# STM32G431C6T6 register map
File version: 1.0
Registers are 32-bit, access not given, reset 0x0 unless marked. A register's access mark holds for its fields unless they carry their own. Offsets are from the block's base; [hi:lo] are bit positions; {n}, {i} and the like mark numbered series; 'fields as' and 'values as' point back to an identical list.

## OPAMP
Base 0x40010300
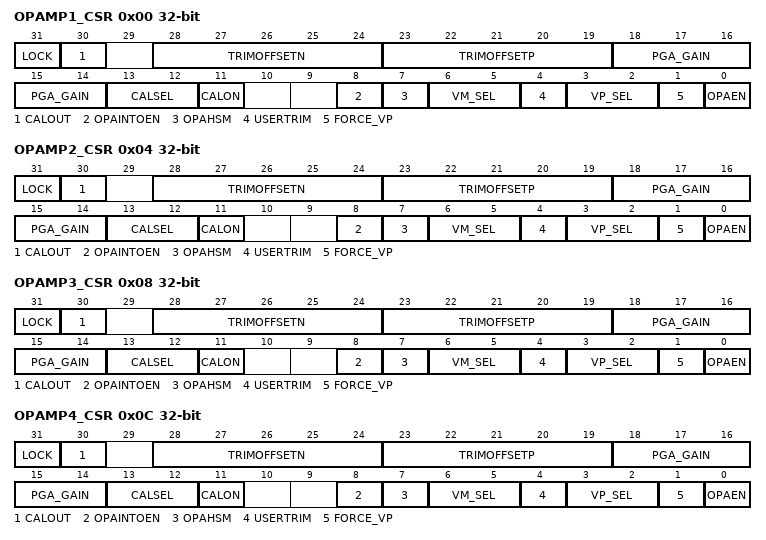
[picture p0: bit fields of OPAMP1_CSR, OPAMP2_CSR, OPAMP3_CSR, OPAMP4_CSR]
0x00 OPAMP1_CSR
  [31] LOCK, [30] CALOUT, [28:24] TRIMOFFSETN, [23:19] TRIMOFFSETP, [18:14] PGA_GAIN, [13:12] CALSEL, [11] CALON, [8] OPAINTOEN, [7] OPAHSM, [6:5] VM_SEL, [4] USERTRIM, [3:2] VP_SEL, [1] FORCE_VP, [0] OPAEN
0x04 OPAMP2_CSR
  fields as OPAMP1_CSR
0x08 OPAMP3_CSR
  fields as OPAMP1_CSR
0x0C OPAMP4_CSR
  fields as OPAMP1_CSR
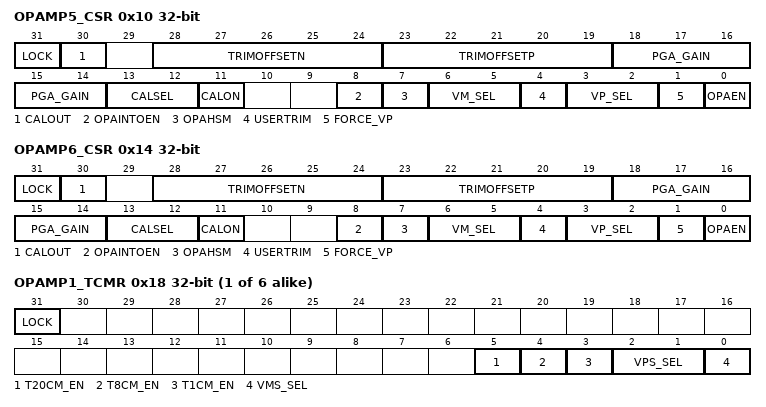
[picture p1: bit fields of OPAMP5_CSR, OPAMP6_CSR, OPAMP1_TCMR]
0x10 OPAMP5_CSR
  fields as OPAMP1_CSR
0x14 OPAMP6_CSR
  fields as OPAMP1_CSR
{0x14+4i} OPAMP{i}_TCMR (i=1..6)
  [31] LOCK, [5] T20CM_EN, [4] T8CM_EN, [3] T1CM_EN, [2:1] VPS_SEL, [0] VMS_SEL

## EXTI
Base 0x40010400
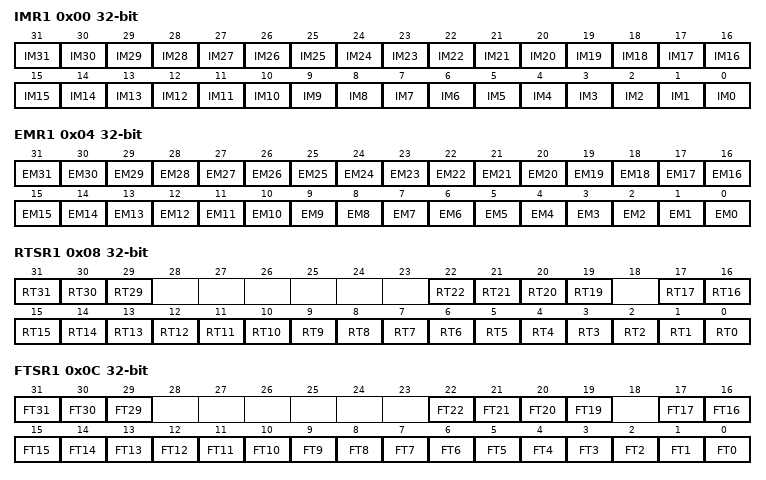
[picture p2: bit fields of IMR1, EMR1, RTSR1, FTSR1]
0x00 IMR1
  [n] IM{n} (n=0..31)
0x04 EMR1
  [n] EM{n} (n=0..31)
0x08 RTSR1
  [31] RT31, [30] RT30, [29] RT29, [n] RT{n} (n=19..22), [n] RT{n} (n=0..17)
0x0C FTSR1
  [31] FT31, [30] FT30, [29] FT29, [n] FT{n} (n=19..22), [n] FT{n} (n=0..17)
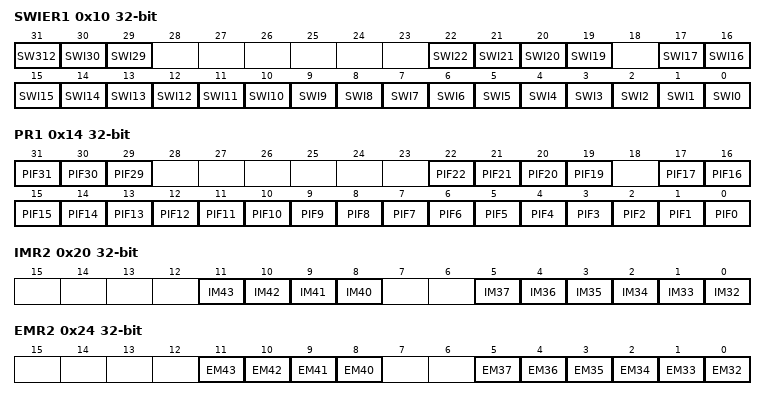
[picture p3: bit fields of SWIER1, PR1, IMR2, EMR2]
0x10 SWIER1
  [31] SW312, [30] SWI30, [29] SWI29, [n] SWI{n} (n=19..22), [n] SWI{n} (n=0..17)
0x14 PR1
  [31] PIF31, [30] PIF30, [29] PIF29, [n] PIF{n} (n=19..22), [n] PIF{n} (n=0..17)
0x20 IMR2
  [n-32] IM{n} (n=40..43), [n-32] IM{n} (n=32..37)
0x24 EMR2
  [n-32] EM{n} (n=40..43), [n-32] EM{n} (n=32..37)
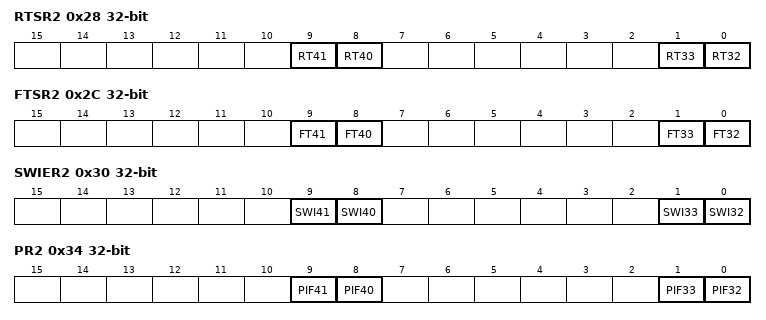
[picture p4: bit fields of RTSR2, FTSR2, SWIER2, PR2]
0x28 RTSR2
  [9] RT41, [8] RT40, [1] RT33, [0] RT32
0x2C FTSR2
  [9] FT41, [8] FT40, [1] FT33, [0] FT32
0x30 SWIER2
  [9] SWI41, [8] SWI40, [1] SWI33, [0] SWI32
0x34 PR2
  [9] PIF41, [8] PIF40, [1] PIF33, [0] PIF32

## TIM15
Base 0x40014000
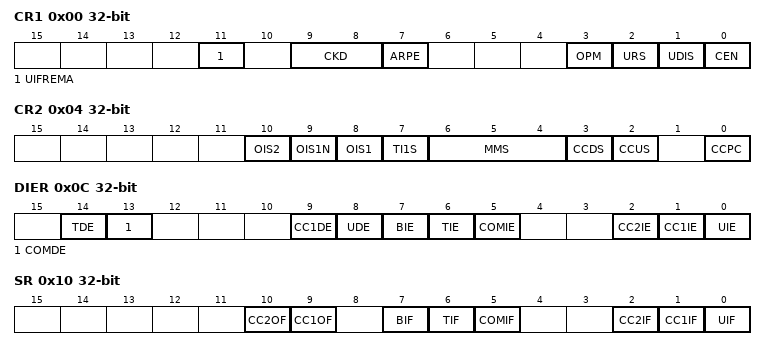
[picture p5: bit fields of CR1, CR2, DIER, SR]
0x00 CR1
  [11] UIFREMA, [9:8] CKD, [7] ARPE, [3] OPM, [2] URS, [1] UDIS, [0] CEN
0x04 CR2
  [10] OIS2, [9] OIS1N, [8] OIS1, [7] TI1S, [6:4] MMS, [3] CCDS, [2] CCUS, [0] CCPC
0x08 SMCR
  [7] MSM, [21:4] TS, [16:0] SMS
0x0C DIER
  [14] TDE, [13] COMDE, [9] CC1DE, [8] UDE, [7] BIE, [6] TIE, [5] COMIE, [2] CC2IE, [1] CC1IE, [0] UIE
0x10 SR
  [10] CC2OF, [9] CC1OF, [7] BIF, [6] TIF, [5] COMIF, [2] CC2IF, [1] CC1IF, [0] UIF
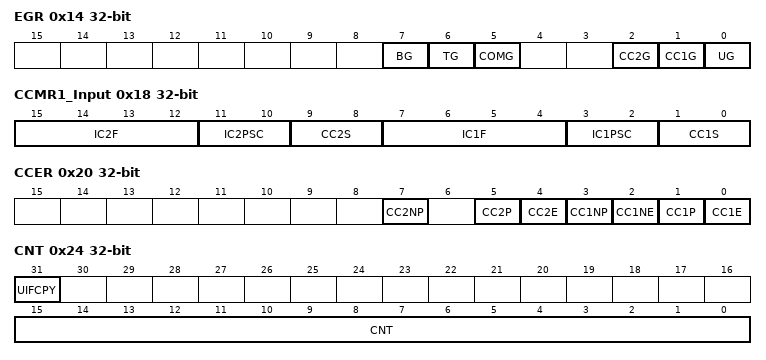
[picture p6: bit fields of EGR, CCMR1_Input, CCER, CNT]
0x14 EGR
  [7] BG, [6] TG, [5] COMG, [2] CC2G, [1] CC1G, [0] UG
0x18 CCMR1_Input
  [15:12] IC2F, [11:10] IC2PSC, [9:8] CC2S, [7:4] IC1F, [3:2] IC1PSC, [1:0] CC1S
0x18 CCMR1_Output
  [15] OC2CE, [24:12] OC2M, [11] OC2PE, [10] OC2FE, [9:8] CC2S, [7] OC1CE, [16:4] OC1M, [3] OC1PE, [2] OC1FE, [1:0] CC1S
0x20 CCER
  [7] CC2NP, [5] CC2P, [4] CC2E, [3] CC1NP, [2] CC1NE, [1] CC1P, [0] CC1E
0x24 CNT
  [31] UIFCPY, [15:0] CNT
0x28 PSC
  [15:0] PSC
0x2C ARR
  [19:0] ARR
0x30 RCR
  [7:0] REP
0x34 CCR1
  [19:0] CCR1
0x38 CCR2
  [19:0] CCR2
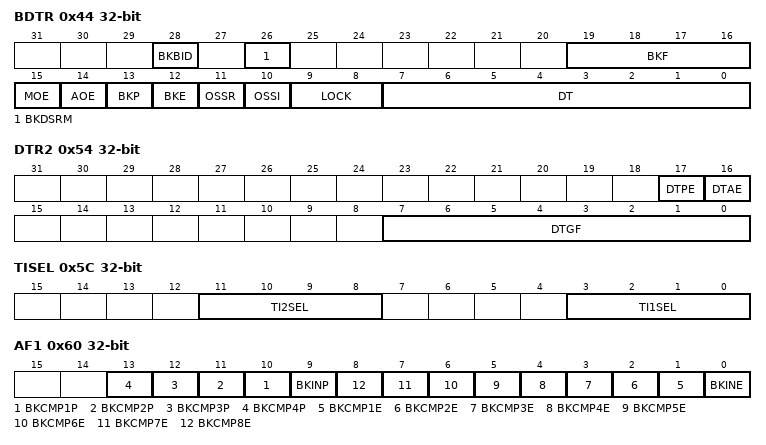
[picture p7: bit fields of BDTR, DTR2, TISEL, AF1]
0x44 BDTR
  [28] BKBID, [26] BKDSRM, [19:16] BKF, [15] MOE, [14] AOE, [13] BKP, [12] BKE, [11] OSSR, [10] OSSI, [9:8] LOCK, [7:0] DT
0x54 DTR2
  [17] DTPE, [16] DTAE, [7:0] DTGF
0x5C TISEL
  [11:8] TI2SEL, [3:0] TI1SEL
0x60 AF1
  [n+9] BKCMP{n}P (n=1..4), [9] BKINP, [n] BKCMP{n}E (n=1..8), [0] BKINE
0x64 AF2
  [18:16] OCRSEL
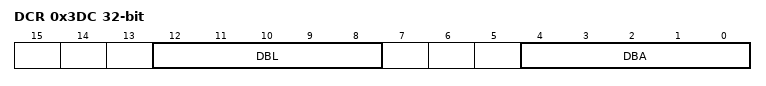
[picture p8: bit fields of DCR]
0x3DC DCR
  [12:8] DBL, [4:0] DBA
0x3E0 DMAR
  [31:0] DMAB

## TIM16
Base 0x40014400
Same registers: TIM17 0x40014800
Registers as TIM15, without SMCR, CCR2; these are added or differ:
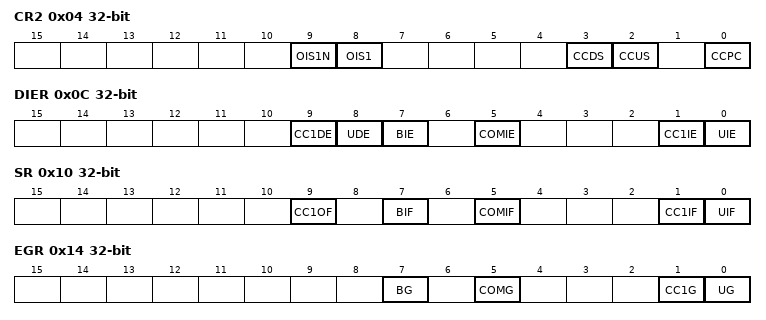
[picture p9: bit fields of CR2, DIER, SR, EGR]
0x04 CR2
  [9] OIS1N, [8] OIS1, [3] CCDS, [2] CCUS, [0] CCPC
0x0C DIER
  [9] CC1DE, [8] UDE, [7] BIE, [5] COMIE, [1] CC1IE, [0] UIE
0x10 SR
  [9] CC1OF, [7] BIF, [5] COMIF, [1] CC1IF, [0] UIF
0x14 EGR
  [7] BG, [5] COMG, [1] CC1G, [0] UG
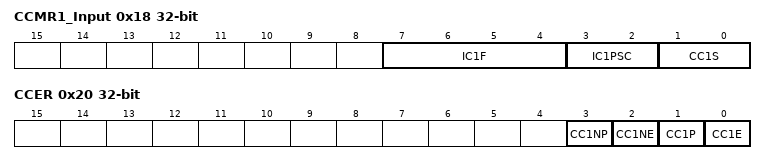
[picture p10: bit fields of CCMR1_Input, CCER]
0x18 CCMR1_Input
  [7:4] IC1F, [3:2] IC1PSC, [1:0] CC1S
0x18 CCMR1_Output
  [7] OC1CE, [16:4] OC1M, [3] OC1PE, [2] OC1FE, [1:0] CC1S
0x20 CCER
  [3] CC1NP, [2] CC1NE, [1] CC1P, [0] CC1E
0x5C TISEL
  [3:0] TI1SEL
0x68 OR1
  [0] HSE32EN

## SAI1
Base 0x40015400
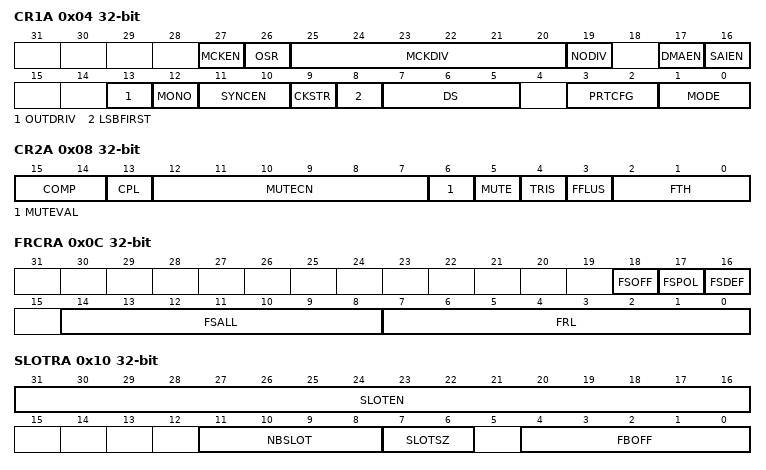
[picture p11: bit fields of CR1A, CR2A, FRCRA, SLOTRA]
0x04 CR1A
  [27] MCKEN, [26] OSR, [25:20] MCKDIV, [19] NODIV, [17] DMAEN, [16] SAIEN, [13] OUTDRIV, [12] MONO, [11:10] SYNCEN, [9] CKSTR, [8] LSBFIRST, [7:5] DS, [3:2] PRTCFG, [1:0] MODE
0x08 CR2A
  [15:14] COMP, [13] CPL, [12:7] MUTECN, [6] MUTEVAL, [5] MUTE, [4] TRIS, [3] FFLUS, [2:0] FTH
0x0C FRCRA
  [18] FSOFF, [17] FSPOL, [16] FSDEF, [14:8] FSALL, [7:0] FRL
0x10 SLOTRA
  [31:16] SLOTEN, [11:8] NBSLOT, [7:6] SLOTSZ, [4:0] FBOFF
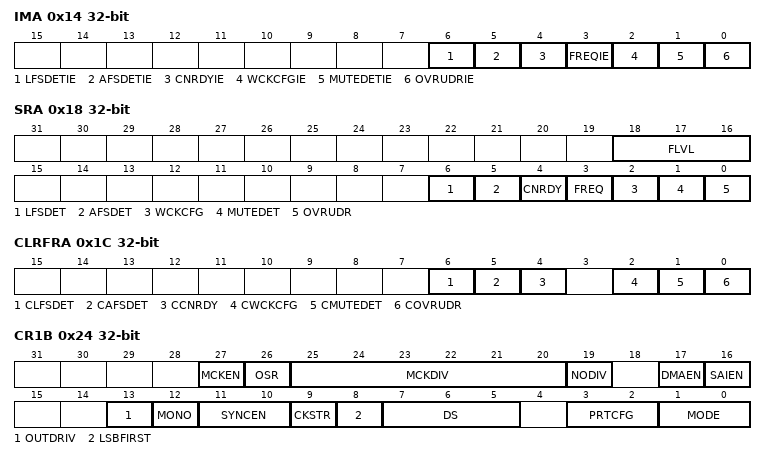
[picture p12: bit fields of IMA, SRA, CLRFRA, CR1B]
0x14 IMA
  [6] LFSDETIE, [5] AFSDETIE, [4] CNRDYIE, [3] FREQIE, [2] WCKCFGIE, [1] MUTEDETIE, [0] OVRUDRIE
0x18 SRA
  [18:16] FLVL, [6] LFSDET, [5] AFSDET, [4] CNRDY, [3] FREQ, [2] WCKCFG, [1] MUTEDET, [0] OVRUDR
0x1C CLRFRA
  [6] CLFSDET, [5] CAFSDET, [4] CCNRDY, [2] CWCKCFG, [1] CMUTEDET, [0] COVRUDR
0x20 DRA
  [31:0] DATA
0x24 CR1B
  fields as CR1A
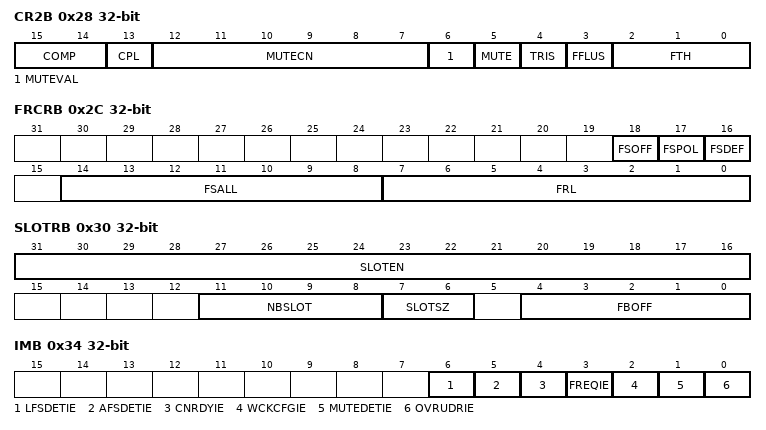
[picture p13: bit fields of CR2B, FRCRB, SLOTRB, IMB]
0x28 CR2B
  fields as CR2A
0x2C FRCRB
  [18] FSOFF, [17] FSPOL, [16] FSDEF, [14:8] FSALL, [7:0] FRL
0x30 SLOTRB
  [31:16] SLOTEN, [11:8] NBSLOT, [7:6] SLOTSZ, [4:0] FBOFF
0x34 IMB
  fields as IMA
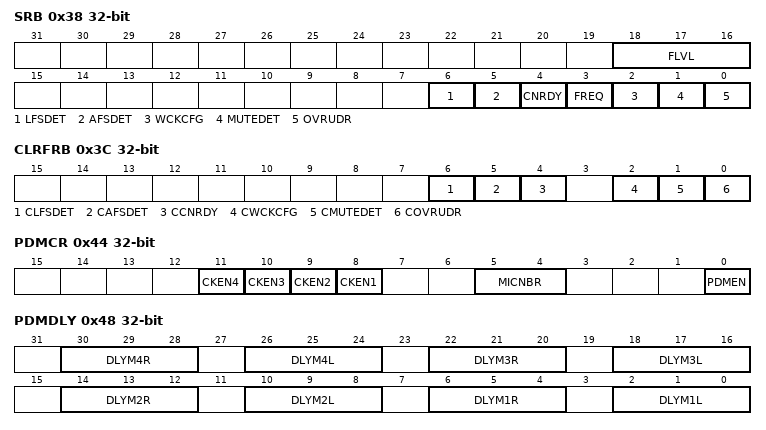
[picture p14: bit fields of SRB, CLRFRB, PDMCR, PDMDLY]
0x38 SRB
  fields as SRA
0x3C CLRFRB
  fields as CLRFRA
0x40 DRB
  [31:0] DATA
0x44 PDMCR
  [n+7] CKEN{n} (n=1..4), [5:4] MICNBR, [0] PDMEN
0x48 PDMDLY
  [8n-2:8n-4] DLYM{n}R (n=1..4), [8n-6:8n-8] DLYM{n}L (n=1..4)
